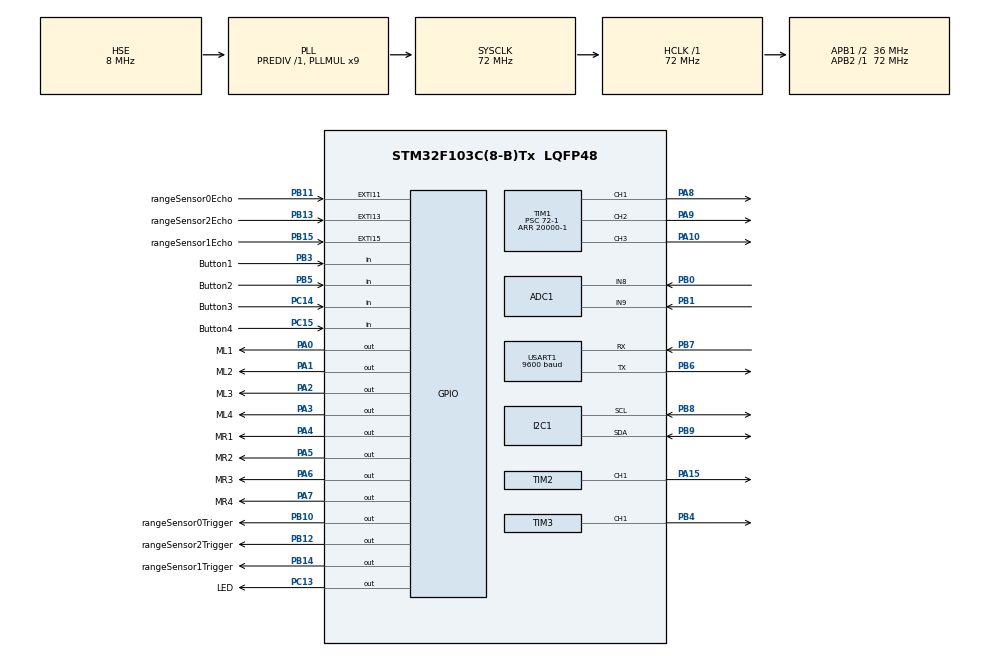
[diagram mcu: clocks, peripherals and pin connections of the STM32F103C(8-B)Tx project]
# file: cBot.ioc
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ADC1.Channel-0\#ChannelRegularConversion=ADC_CHANNEL_8
ADC1.Channel-1\#ChannelRegularConversion=ADC_CHANNEL_9
ADC1.NbrOfConversion=2
ADC1.NbrOfConversionFlag=1
ADC1.Rank-0\#ChannelRegularConversion=1
ADC1.Rank-1\#ChannelRegularConversion=2
ADC1.SamplingTime-0\#ChannelRegularConversion=ADC_SAMPLETIME_239CYCLES_5
ADC1.SamplingTime-1\#ChannelRegularConversion=ADC_SAMPLETIME_239CYCLES_5
ADC1.master=1
Dma.ADC1.0.Direction=DMA_PERIPH_TO_MEMORY
Dma.ADC1.0.Instance=DMA1_Channel1
Dma.ADC1.0.MemDataAlignment=DMA_MDATAALIGN_HALFWORD
Dma.ADC1.0.MemInc=DMA_MINC_ENABLE
Dma.ADC1.0.Mode=DMA_NORMAL
Dma.ADC1.0.PeriphDataAlignment=DMA_PDATAALIGN_HALFWORD
Dma.ADC1.0.PeriphInc=DMA_PINC_DISABLE
Dma.ADC1.0.Priority=DMA_PRIORITY_LOW
Dma.Request0=ADC1
Dma.Request1=TIM2_CH1
Dma.TIM2_CH1.1.Direction=DMA_MEMORY_TO_PERIPH
Dma.TIM2_CH1.1.Instance=DMA1_Channel5
Dma.TIM2_CH1.1.MemDataAlignment=DMA_MDATAALIGN_BYTE
Dma.TIM2_CH1.1.MemInc=DMA_MINC_ENABLE
Dma.TIM2_CH1.1.Mode=DMA_NORMAL
Dma.TIM2_CH1.1.PeriphDataAlignment=DMA_PDATAALIGN_HALFWORD
Dma.TIM2_CH1.1.PeriphInc=DMA_PINC_DISABLE
Dma.TIM2_CH1.1.Priority=DMA_PRIORITY_MEDIUM
I2C1.I2C_Mode=I2C_Fast
Mcu.Family=STM32F1
Mcu.Name=STM32F103C(8-B)Tx
Mcu.Package=LQFP48
NVIC.DMA1_Channel1_IRQn=true\:0\:0\:false\:false\:true\:false\:true\:true
NVIC.DMA1_Channel5_IRQn=true\:0\:0\:false\:false\:true\:false\:true\:true
NVIC.EXTI15_10_IRQn=true\:0\:0\:false\:false\:true\:true\:true\:true
NVIC.PriorityGroup=NVIC_PRIORITYGROUP_4
NVIC.TIM4_IRQn=true\:0\:0\:false\:false\:true\:true\:true\:true
NVIC.USART1_IRQn=true\:0\:0\:false\:false\:true\:true\:true\:true
PA0-WKUP.GPIO_Label=ML1
PA0-WKUP.Signal=GPIO_Output
PA1.GPIO_Label=ML2
PA1.Signal=GPIO_Output
PA10.Signal=S_TIM1_CH3
PA13.Mode=Serial_Wire
PA13.Signal=SYS_JTMS-SWDIO
PA14.Mode=Serial_Wire
PA14.Signal=SYS_JTCK-SWCLK
PA15.Signal=S_TIM2_CH1_ETR
PA2.GPIO_Label=ML3
PA2.Signal=GPIO_Output
PA3.GPIO_Label=ML4
PA3.Signal=GPIO_Output
PA4.GPIO_Label=MR1
PA4.Signal=GPIO_Output
PA5.GPIO_Label=MR2
PA5.Signal=GPIO_Output
PA6.GPIO_Label=MR3
PA6.Signal=GPIO_Output
PA7.GPIO_Label=MR4
PA7.Signal=GPIO_Output
PA8.Signal=S_TIM1_CH1
PA9.Signal=S_TIM1_CH2
PB0.Signal=ADCx_IN8
PB1.Signal=ADCx_IN9
PB10.GPIO_Label=rangeSensor0Trigger
PB10.Signal=GPIO_Output
PB11.GPIO_Label=rangeSensor0Echo
PB11.GPIO_ModeDefaultEXTI=GPIO_MODE_IT_RISING_FALLING
PB11.Signal=GPXTI11
PB12.GPIO_Label=rangeSensor2Trigger
PB12.Signal=GPIO_Output
PB13.GPIO_Label=rangeSensor2Echo
PB13.GPIO_ModeDefaultEXTI=GPIO_MODE_IT_RISING_FALLING
PB13.Signal=GPXTI13
PB14.GPIO_Label=rangeSensor1Trigger
PB14.Signal=GPIO_Output
PB15.GPIO_Label=rangeSensor1Echo
PB15.GPIO_ModeDefaultEXTI=GPIO_MODE_IT_RISING_FALLING
PB15.Signal=GPXTI15
PB3.GPIO_Label=Button1
PB3.GPIO_PuPd=GPIO_PULLUP
PB3.Signal=GPIO_Input
PB4.Signal=S_TIM3_CH1
PB5.GPIO_Label=Button2
PB5.GPIO_PuPd=GPIO_PULLUP
PB5.Signal=GPIO_Input
PB6.Mode=Asynchronous
PB6.Signal=USART1_TX
PB7.Mode=Asynchronous
PB7.Signal=USART1_RX
PB8.GPIO_Pu=GPIO_PULLUP
PB8.Mode=I2C
PB8.Signal=I2C1_SCL
PB9.GPIO_Pu=GPIO_PULLUP
PB9.Mode=I2C
PB9.Signal=I2C1_SDA
PC13-TAMPER-RTC.GPIO_Label=LED
PC13-TAMPER-RTC.Signal=GPIO_Output
PC14-OSC32_IN.GPIO_Label=Button3
PC14-OSC32_IN.GPIO_PuPd=GPIO_PULLUP
PC14-OSC32_IN.Signal=GPIO_Input
PC15-OSC32_OUT.GPIO_Label=Button4
PC15-OSC32_OUT.GPIO_PuPd=GPIO_PULLUP
PC15-OSC32_OUT.Signal=GPIO_Input
PD0-OSC_IN.Mode=HSE-External-Oscillator
PD0-OSC_IN.Signal=RCC_OSC_IN
PD1-OSC_OUT.Mode=HSE-External-Oscillator
PD1-OSC_OUT.Signal=RCC_OSC_OUT
ProjectManager.HeapSize=0x1000
ProjectManager.StackSize=0x0800
ProjectManager.TargetToolchain=STM32CubeIDE
RCC.ADCPresc=RCC_ADCPCLK2_DIV6
RCC.AHBFreq_Value=72000000
RCC.APB1CLKDivider=RCC_HCLK_DIV2
RCC.APB1Freq_Value=36000000
RCC.APB1TimFreq_Value=72000000
RCC.APB2Freq_Value=72000000
RCC.APB2TimFreq_Value=72000000
RCC.HCLKFreq_Value=72000000
RCC.HSE_Timout=100
RCC.PLLMUL=RCC_PLL_MUL9
RCC.PLLSourceVirtual=RCC_PLLSOURCE_HSE
RCC.SYSCLKFreq_VALUE=72000000
RCC.SYSCLKSource=RCC_SYSCLKSOURCE_PLLCLK
RCC.USBFreq_Value=72000000
SH.ADCx_IN8.0=ADC1_IN8,IN8
SH.ADCx_IN9.0=ADC1_IN9,IN9
SH.S_TIM1_CH1.0=TIM1_CH1,PWM Generation1 CH1
SH.S_TIM1_CH2.0=TIM1_CH2,PWM Generation2 CH2
SH.S_TIM1_CH3.0=TIM1_CH3,PWM Generation3 CH3
SH.S_TIM2_CH1_ETR.0=TIM2_CH1,PWM Generation1 CH1
SH.S_TIM3_CH1.0=TIM3_CH1,Output Compare1 CH1
TIM1.Channel-PWM\ Generation1\ CH1=TIM_CHANNEL_1
TIM1.Channel-PWM\ Generation2\ CH2=TIM_CHANNEL_2
TIM1.Channel-PWM\ Generation3\ CH3=TIM_CHANNEL_3
TIM1.Period=20000-1
TIM1.Prescaler=72-1
TIM2.Channel-PWM\ Generation1\ CH1=TIM_CHANNEL_1
TIM2.Period=90-1
TIM3.Channel-Output\ Compare1\ CH1=TIM_CHANNEL_1
TIM3.OCMode_1=TIM_OCMODE_TOGGLE
TIM3.Prescaler=4-1
TIM4.AutoReloadPreload=TIM_AUTORELOAD_PRELOAD_DISABLE
TIM4.Period=100-1
TIM4.Prescaler=72-1
USART1.BaudRate=9600
USART1.VirtualMode=VM_ASYNC
VP_TIM4_VS_ClockSourceINT.Mode=Internal
board=custom

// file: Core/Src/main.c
/* USER CODE BEGIN Header */
/**
  ******************************************************************************
  * @file           : main.c
  * @brief          : Main program body
  ******************************************************************************
  * @attention
  *
  * Copyright (c) 2023 STMicroelectronics.
  * All rights reserved.
  *
  * This software is licensed under terms that can be found in the LICENSE file
  * in the root directory of this software component.
  * If no LICENSE file comes with this software, it is provided AS-IS.
  *
  ******************************************************************************
  */
/* USER CODE END Header */
#include "main.h"

/* USER CODE BEGIN Includes */
#include "cBot.h"
#include "cBotApp.h"
#include "marioSong.h"
/* USER CODE END Includes */

ADC_HandleTypeDef hadc1;
DMA_HandleTypeDef hdma_adc1;

I2C_HandleTypeDef hi2c1;

TIM_HandleTypeDef htim1;
TIM_HandleTypeDef htim2;
TIM_HandleTypeDef htim3;
TIM_HandleTypeDef htim4;
DMA_HandleTypeDef hdma_tim2_ch1;

void SystemClock_Config(void);
static void MX_GPIO_Init(void);
static void MX_DMA_Init(void);
static void MX_ADC1_Init(void);
static void MX_I2C1_Init(void);
static void MX_TIM1_Init(void);
static void MX_TIM2_Init(void);
static void MX_TIM3_Init(void);
static void MX_USART1_UART_Init(void);
static void MX_TIM4_Init(void);

/* USER CODE BEGIN 0 */
extern void initialise_monitor_handles(void);
/* USER CODE END 0 */

int main(void)
{

  /* MCU Configuration--------------------------------------------------------*/

  /* Reset of all peripherals, Initializes the Flash interface and the Systick. */
  HAL_Init();

  /* Configure the system clock */
  SystemClock_Config();

  /* Initialize all configured peripherals */
  MX_GPIO_Init();
  MX_DMA_Init();
  MX_ADC1_Init();
  MX_I2C1_Init();
  MX_TIM1_Init();
  MX_TIM2_Init();
  MX_TIM3_Init();
  MX_USART1_UART_Init();
  MX_TIM4_Init();
  /* USER CODE BEGIN 2 */
#ifdef DEBUG
  initialise_monitor_handles();
#endif
  cBot_init();
  init();
  /* USER CODE END 2 */

  /* Infinite loop */
  /* USER CODE BEGIN WHILE */
  while (1)
  {
	  loop();
  }
    /* USER CODE END WHILE */

}

void SystemClock_Config(void)
{
  RCC_OscInitTypeDef RCC_OscInitStruct = {0};
  RCC_ClkInitTypeDef RCC_ClkInitStruct = {0};
  RCC_PeriphCLKInitTypeDef PeriphClkInit = {0};

  /** Initializes the RCC Oscillators according to the specified parameters
  * in the RCC_OscInitTypeDef structure.
  */
  RCC_OscInitStruct.OscillatorType = RCC_OSCILLATORTYPE_HSE;
  RCC_OscInitStruct.HSEState = RCC_HSE_ON;
  RCC_OscInitStruct.HSEPredivValue = RCC_HSE_PREDIV_DIV1;
  RCC_OscInitStruct.HSIState = RCC_HSI_ON;
  RCC_OscInitStruct.PLL.PLLState = RCC_PLL_ON;
  RCC_OscInitStruct.PLL.PLLSource = RCC_PLLSOURCE_HSE;
  RCC_OscInitStruct.PLL.PLLMUL = RCC_PLL_MUL9;
  if (HAL_RCC_OscConfig(&RCC_OscInitStruct) != HAL_OK)
  {
    Error_Handler();
  }

  /** Initializes the CPU, AHB and APB buses clocks
  */
  RCC_ClkInitStruct.ClockType = RCC_CLOCKTYPE_HCLK|RCC_CLOCKTYPE_SYSCLK
                              |RCC_CLOCKTYPE_PCLK1|RCC_CLOCKTYPE_PCLK2;
  RCC_ClkInitStruct.SYSCLKSource = RCC_SYSCLKSOURCE_PLLCLK;
  RCC_ClkInitStruct.AHBCLKDivider = RCC_SYSCLK_DIV1;
  RCC_ClkInitStruct.APB1CLKDivider = RCC_HCLK_DIV2;
  RCC_ClkInitStruct.APB2CLKDivider = RCC_HCLK_DIV1;

  if (HAL_RCC_ClockConfig(&RCC_ClkInitStruct, FLASH_LATENCY_2) != HAL_OK)
  {
    Error_Handler();
  }
  PeriphClkInit.PeriphClockSelection = RCC_PERIPHCLK_ADC;
  PeriphClkInit.AdcClockSelection = RCC_ADCPCLK2_DIV6;
  if (HAL_RCCEx_PeriphCLKConfig(&PeriphClkInit) != HAL_OK)
  {
    Error_Handler();
  }
}

static void MX_ADC1_Init(void)
{

  ADC_ChannelConfTypeDef sConfig = {0};

  /** Common config
  */
  hadc1.Instance = ADC1;
  hadc1.Init.ScanConvMode = ADC_SCAN_ENABLE;
  hadc1.Init.ContinuousConvMode = DISABLE;
  hadc1.Init.DiscontinuousConvMode = DISABLE;
  hadc1.Init.ExternalTrigConv = ADC_SOFTWARE_START;
  hadc1.Init.DataAlign = ADC_DATAALIGN_RIGHT;
  hadc1.Init.NbrOfConversion = 2;
  if (HAL_ADC_Init(&hadc1) != HAL_OK)
  {
    Error_Handler();
  }

  /** Configure Regular Channel
  */
  sConfig.Channel = ADC_CHANNEL_8;
  sConfig.Rank = ADC_REGULAR_RANK_1;
  sConfig.SamplingTime = ADC_SAMPLETIME_239CYCLES_5;
  if (HAL_ADC_ConfigChannel(&hadc1, &sConfig) != HAL_OK)
  {
    Error_Handler();
  }

  /** Configure Regular Channel
  */
  sConfig.Channel = ADC_CHANNEL_9;
  sConfig.Rank = ADC_REGULAR_RANK_2;
  if (HAL_ADC_ConfigChannel(&hadc1, &sConfig) != HAL_OK)
  {
    Error_Handler();
  }

}

static void MX_I2C1_Init(void)
{

  hi2c1.Instance = I2C1;
  hi2c1.Init.ClockSpeed = 400000;
  hi2c1.Init.DutyCycle = I2C_DUTYCYCLE_2;
  hi2c1.Init.OwnAddress1 = 0;
  hi2c1.Init.AddressingMode = I2C_ADDRESSINGMODE_7BIT;
  hi2c1.Init.DualAddressMode = I2C_DUALADDRESS_DISABLE;
  hi2c1.Init.OwnAddress2 = 0;
  hi2c1.Init.GeneralCallMode = I2C_GENERALCALL_DISABLE;
  hi2c1.Init.NoStretchMode = I2C_NOSTRETCH_DISABLE;
  if (HAL_I2C_Init(&hi2c1) != HAL_OK)
  {
    Error_Handler();
  }

}

static void MX_TIM1_Init(void)
{

  TIM_MasterConfigTypeDef sMasterConfig = {0};
  TIM_OC_InitTypeDef sConfigOC = {0};
  TIM_BreakDeadTimeConfigTypeDef sBreakDeadTimeConfig = {0};

  htim1.Instance = TIM1;
  htim1.Init.Prescaler = 72-1;
  htim1.Init.CounterMode = TIM_COUNTERMODE_UP;
  htim1.Init.Period = 20000-1;
  htim1.Init.ClockDivision = TIM_CLOCKDIVISION_DIV1;
  htim1.Init.RepetitionCounter = 0;
  htim1.Init.AutoReloadPreload = TIM_AUTORELOAD_PRELOAD_DISABLE;
  if (HAL_TIM_PWM_Init(&htim1) != HAL_OK)
  {
    Error_Handler();
  }
  sMasterConfig.MasterOutputTrigger = TIM_TRGO_RESET;
  sMasterConfig.MasterSlaveMode = TIM_MASTERSLAVEMODE_DISABLE;
  if (HAL_TIMEx_MasterConfigSynchronization(&htim1, &sMasterConfig) != HAL_OK)
  {
    Error_Handler();
  }
  sConfigOC.OCMode = TIM_OCMODE_PWM1;
  sConfigOC.Pulse = 0;
  sConfigOC.OCPolarity = TIM_OCPOLARITY_HIGH;
  sConfigOC.OCNPolarity = TIM_OCNPOLARITY_HIGH;
  sConfigOC.OCFastMode = TIM_OCFAST_DISABLE;
  sConfigOC.OCIdleState = TIM_OCIDLESTATE_RESET;
  sConfigOC.OCNIdleState = TIM_OCNIDLESTATE_RESET;
  if (HAL_TIM_PWM_ConfigChannel(&htim1, &sConfigOC, TIM_CHANNEL_1) != HAL_OK)
  {
    Error_Handler();
  }
  if (HAL_TIM_PWM_ConfigChannel(&htim1, &sConfigOC, TIM_CHANNEL_2) != HAL_OK)
  {
    Error_Handler();
  }
  if (HAL_TIM_PWM_ConfigChannel(&htim1, &sConfigOC, TIM_CHANNEL_3) != HAL_OK)
  {
    Error_Handler();
  }
  sBreakDeadTimeConfig.OffStateRunMode = TIM_OSSR_DISABLE;
  sBreakDeadTimeConfig.OffStateIDLEMode = TIM_OSSI_DISABLE;
  sBreakDeadTimeConfig.LockLevel = TIM_LOCKLEVEL_OFF;
  sBreakDeadTimeConfig.DeadTime = 0;
  sBreakDeadTimeConfig.BreakState = TIM_BREAK_DISABLE;
  sBreakDeadTimeConfig.BreakPolarity = TIM_BREAKPOLARITY_HIGH;
  sBreakDeadTimeConfig.AutomaticOutput = TIM_AUTOMATICOUTPUT_DISABLE;
  if (HAL_TIMEx_ConfigBreakDeadTime(&htim1, &sBreakDeadTimeConfig) != HAL_OK)
  {
    Error_Handler();
  }
  HAL_TIM_MspPostInit(&htim1);

}

static void MX_TIM2_Init(void)
{

  TIM_MasterConfigTypeDef sMasterConfig = {0};
  TIM_OC_InitTypeDef sConfigOC = {0};

  htim2.Instance = TIM2;
  htim2.Init.Prescaler = 0;
  htim2.Init.CounterMode = TIM_COUNTERMODE_UP;
  htim2.Init.Period = 90-1;
  htim2.Init.ClockDivision = TIM_CLOCKDIVISION_DIV1;
  htim2.Init.AutoReloadPreload = TIM_AUTORELOAD_PRELOAD_DISABLE;
  if (HAL_TIM_PWM_Init(&htim2) != HAL_OK)
  {
    Error_Handler();
  }
  sMasterConfig.MasterOutputTrigger = TIM_TRGO_RESET;
  sMasterConfig.MasterSlaveMode = TIM_MASTERSLAVEMODE_DISABLE;
  if (HAL_TIMEx_MasterConfigSynchronization(&htim2, &sMasterConfig) != HAL_OK)
  {
    Error_Handler();
  }
  sConfigOC.OCMode = TIM_OCMODE_PWM1;
  sConfigOC.Pulse = 0;
  sConfigOC.OCPolarity = TIM_OCPOLARITY_HIGH;
  sConfigOC.OCFastMode = TIM_OCFAST_DISABLE;
  if (HAL_TIM_PWM_ConfigChannel(&htim2, &sConfigOC, TIM_CHANNEL_1) != HAL_OK)
  {
    Error_Handler();
  }
  HAL_TIM_MspPostInit(&htim2);

}

static void MX_TIM3_Init(void)
{

  TIM_MasterConfigTypeDef sMasterConfig = {0};
  TIM_OC_InitTypeDef sConfigOC = {0};

  htim3.Instance = TIM3;
  htim3.Init.Prescaler = 4-1;
  htim3.Init.CounterMode = TIM_COUNTERMODE_UP;
  htim3.Init.Period = 65535;
  htim3.Init.ClockDivision = TIM_CLOCKDIVISION_DIV1;
  htim3.Init.AutoReloadPreload = TIM_AUTORELOAD_PRELOAD_DISABLE;
  if (HAL_TIM_OC_Init(&htim3) != HAL_OK)
  {
    Error_Handler();
  }
  sMasterConfig.MasterOutputTrigger = TIM_TRGO_RESET;
  sMasterConfig.MasterSlaveMode = TIM_MASTERSLAVEMODE_DISABLE;
  if (HAL_TIMEx_MasterConfigSynchronization(&htim3, &sMasterConfig) != HAL_OK)
  {
    Error_Handler();
  }
  sConfigOC.OCMode = TIM_OCMODE_TOGGLE;
  sConfigOC.Pulse = 0;
  sConfigOC.OCPolarity = TIM_OCPOLARITY_HIGH;
  sConfigOC.OCFastMode = TIM_OCFAST_DISABLE;
  if (HAL_TIM_OC_ConfigChannel(&htim3, &sConfigOC, TIM_CHANNEL_1) != HAL_OK)
  {
    Error_Handler();
  }
  HAL_TIM_MspPostInit(&htim3);

}

static void MX_TIM4_Init(void)
{

  TIM_ClockConfigTypeDef sClockSourceConfig = {0};
  TIM_MasterConfigTypeDef sMasterConfig = {0};

  htim4.Instance = TIM4;
  htim4.Init.Prescaler = 72-1;
  htim4.Init.CounterMode = TIM_COUNTERMODE_UP;
  htim4.Init.Period = 100-1;
  htim4.Init.ClockDivision = TIM_CLOCKDIVISION_DIV1;
  htim4.Init.AutoReloadPreload = TIM_AUTORELOAD_PRELOAD_DISABLE;
  if (HAL_TIM_Base_Init(&htim4) != HAL_OK)
  {
    Error_Handler();
  }
  sClockSourceConfig.ClockSource = TIM_CLOCKSOURCE_INTERNAL;
  if (HAL_TIM_ConfigClockSource(&htim4, &sClockSourceConfig) != HAL_OK)
  {
    Error_Handler();
  }
  sMasterConfig.MasterOutputTrigger = TIM_TRGO_RESET;
  sMasterConfig.MasterSlaveMode = TIM_MASTERSLAVEMODE_DISABLE;
  if (HAL_TIMEx_MasterConfigSynchronization(&htim4, &sMasterConfig) != HAL_OK)
  {
    Error_Handler();
  }

}

static void MX_USART1_UART_Init(void)
{

  LL_USART_InitTypeDef USART_InitStruct = {0};

  LL_GPIO_InitTypeDef GPIO_InitStruct = {0};

  /* Peripheral clock enable */
  LL_APB2_GRP1_EnableClock(LL_APB2_GRP1_PERIPH_USART1);

  LL_APB2_GRP1_EnableClock(LL_APB2_GRP1_PERIPH_GPIOB);
  /**USART1 GPIO Configuration
  PB6   ------> USART1_TX
  PB7   ------> USART1_RX
  */
  GPIO_InitStruct.Pin = LL_GPIO_PIN_6;
  GPIO_InitStruct.Mode = LL_GPIO_MODE_ALTERNATE;
  GPIO_InitStruct.Speed = LL_GPIO_SPEED_FREQ_HIGH;
  GPIO_InitStruct.OutputType = LL_GPIO_OUTPUT_PUSHPULL;
  LL_GPIO_Init(GPIOB, &GPIO_InitStruct);

  GPIO_InitStruct.Pin = LL_GPIO_PIN_7;
  GPIO_InitStruct.Mode = LL_GPIO_MODE_FLOATING;
  LL_GPIO_Init(GPIOB, &GPIO_InitStruct);

  LL_GPIO_AF_EnableRemap_USART1();

  /* USART1 interrupt Init */
  NVIC_SetPriority(USART1_IRQn, NVIC_EncodePriority(NVIC_GetPriorityGrouping(),0, 0));
  NVIC_EnableIRQ(USART1_IRQn);

  USART_InitStruct.BaudRate = 115200;
  USART_InitStruct.DataWidth = LL_USART_DATAWIDTH_8B;
  USART_InitStruct.StopBits = LL_USART_STOPBITS_1;
  USART_InitStruct.Parity = LL_USART_PARITY_NONE;
  USART_InitStruct.TransferDirection = LL_USART_DIRECTION_TX_RX;
  USART_InitStruct.HardwareFlowControl = LL_USART_HWCONTROL_NONE;
  USART_InitStruct.OverSampling = LL_USART_OVERSAMPLING_16;
  LL_USART_Init(USART1, &USART_InitStruct);
  LL_USART_ConfigAsyncMode(USART1);
  LL_USART_Enable(USART1);

}

static void MX_DMA_Init(void)
{

  /* DMA controller clock enable */
  __HAL_RCC_DMA1_CLK_ENABLE();

  /* DMA interrupt init */
  /* DMA1_Channel1_IRQn interrupt configuration */
  HAL_NVIC_SetPriority(DMA1_Channel1_IRQn, 3, 0);
  HAL_NVIC_EnableIRQ(DMA1_Channel1_IRQn);
  /* DMA1_Channel5_IRQn interrupt configuration */
  HAL_NVIC_SetPriority(DMA1_Channel5_IRQn, 0, 0);
  HAL_NVIC_EnableIRQ(DMA1_Channel5_IRQn);

}

static void MX_GPIO_Init(void)
{
  GPIO_InitTypeDef GPIO_InitStruct = {0};

  /* GPIO Ports Clock Enable */
  __HAL_RCC_GPIOC_CLK_ENABLE();
  __HAL_RCC_GPIOD_CLK_ENABLE();
  __HAL_RCC_GPIOA_CLK_ENABLE();
  __HAL_RCC_GPIOB_CLK_ENABLE();

  /*Configure GPIO pin Output Level */
  HAL_GPIO_WritePin(LED_GPIO_Port, LED_Pin, GPIO_PIN_RESET);

  /*Configure GPIO pin Output Level */
  HAL_GPIO_WritePin(GPIOA, ML1_Pin|ML2_Pin|ML3_Pin|ML4_Pin
                          |MR1_Pin|MR2_Pin|MR3_Pin|MR4_Pin, GPIO_PIN_RESET);

  /*Configure GPIO pin Output Level */
  HAL_GPIO_WritePin(GPIOB, rangeSensor0Trigger_Pin|rangeSensor2Trigger_Pin|rangeSensor1Trigger_Pin, GPIO_PIN_RESET);

  /*Configure GPIO pin : LED_Pin */
  GPIO_InitStruct.Pin = LED_Pin;
  GPIO_InitStruct.Mode = GPIO_MODE_OUTPUT_PP;
  GPIO_InitStruct.Pull = GPIO_NOPULL;
  GPIO_InitStruct.Speed = GPIO_SPEED_FREQ_LOW;
  HAL_GPIO_Init(LED_GPIO_Port, &GPIO_InitStruct);

  /*Configure GPIO pins : Button3_Pin Button4_Pin */
  GPIO_InitStruct.Pin = Button3_Pin|Button4_Pin;
  GPIO_InitStruct.Mode = GPIO_MODE_INPUT;
  GPIO_InitStruct.Pull = GPIO_PULLUP;
  HAL_GPIO_Init(GPIOC, &GPIO_InitStruct);

  /*Configure GPIO pins : ML1_Pin ML2_Pin ML3_Pin ML4_Pin
                           MR1_Pin MR2_Pin MR3_Pin MR4_Pin */
  GPIO_InitStruct.Pin = ML1_Pin|ML2_Pin|ML3_Pin|ML4_Pin
                          |MR1_Pin|MR2_Pin|MR3_Pin|MR4_Pin;
  GPIO_InitStruct.Mode = GPIO_MODE_OUTPUT_PP;
  GPIO_InitStruct.Pull = GPIO_NOPULL;
  GPIO_InitStruct.Speed = GPIO_SPEED_FREQ_LOW;
  HAL_GPIO_Init(GPIOA, &GPIO_InitStruct);

  /*Configure GPIO pins : rangeSensor0Trigger_Pin rangeSensor2Trigger_Pin rangeSensor1Trigger_Pin */
  GPIO_InitStruct.Pin = rangeSensor0Trigger_Pin|rangeSensor2Trigger_Pin|rangeSensor1Trigger_Pin;
  GPIO_InitStruct.Mode = GPIO_MODE_OUTPUT_PP;
  GPIO_InitStruct.Pull = GPIO_NOPULL;
  GPIO_InitStruct.Speed = GPIO_SPEED_FREQ_LOW;
  HAL_GPIO_Init(GPIOB, &GPIO_InitStruct);

  /*Configure GPIO pins : rangeSensor0Echo_Pin rangeSensor2Echo_Pin rangeSensor1Echo_Pin */
  GPIO_InitStruct.Pin = rangeSensor0Echo_Pin|rangeSensor2Echo_Pin|rangeSensor1Echo_Pin;
  GPIO_InitStruct.Mode = GPIO_MODE_IT_RISING_FALLING;
  GPIO_InitStruct.Pull = GPIO_NOPULL;
  HAL_GPIO_Init(GPIOB, &GPIO_InitStruct);

  /*Configure GPIO pins : Button1_Pin Button2_Pin */
  GPIO_InitStruct.Pin = Button1_Pin|Button2_Pin;
  GPIO_InitStruct.Mode = GPIO_MODE_INPUT;
  GPIO_InitStruct.Pull = GPIO_PULLUP;
  HAL_GPIO_Init(GPIOB, &GPIO_InitStruct);

  /* EXTI interrupt init*/
  HAL_NVIC_SetPriority(EXTI15_10_IRQn, 0, 0);
  HAL_NVIC_EnableIRQ(EXTI15_10_IRQn);

}

void Error_Handler(void)
{
  __disable_irq();
  while (1)
  {
  }
}
